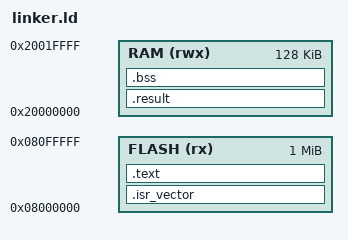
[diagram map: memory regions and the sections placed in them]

ENTRY(Reset_Handler)

MEMORY
{
    FLASH (rx)  : ORIGIN = 0x08000000, LENGTH = 1M
    RAM   (rwx) : ORIGIN = 0x20000000, LENGTH = 128K
}

_estack = ORIGIN(RAM) + LENGTH(RAM);

SECTIONS
{
    .isr_vector :
    {
        KEEP(*(.isr_vector))
    } > FLASH

    .text :
    {
        *(.text*)
        *(.rodata*)
    } > FLASH

    .result (NOLOAD) :
    {
        KEEP(*(.result))
    } > RAM

    .bss (NOLOAD) :
    {
        *(.bss*)
        *(COMMON)
    } > RAM
}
